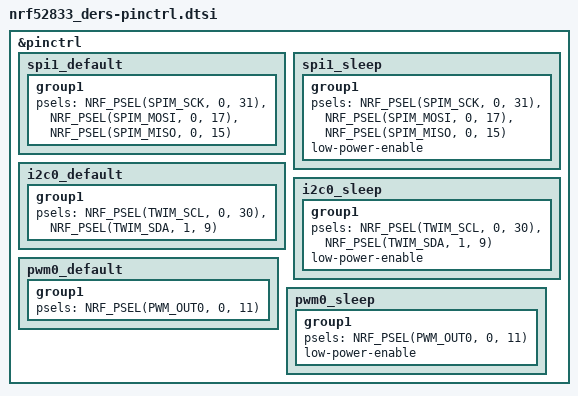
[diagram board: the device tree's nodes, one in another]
/* SPDX-License-Identifier: Apache-2.0 */

#include <dt-bindings/pinctrl/nrf-pinctrl.h>

&pinctrl {
	/* SPI1: SCK=P0.31, MOSI=P0.17, MISO=P0.15 */
	spi1_default: spi1_default {
		group1 {
			psels = <NRF_PSEL(SPIM_SCK,  0, 31)>,
			        <NRF_PSEL(SPIM_MOSI, 0, 17)>,
			        <NRF_PSEL(SPIM_MISO, 0, 15)>;
		};
	};
	spi1_sleep: spi1_sleep {
		group1 {
			psels = <NRF_PSEL(SPIM_SCK,  0, 31)>,
			        <NRF_PSEL(SPIM_MOSI, 0, 17)>,
			        <NRF_PSEL(SPIM_MISO, 0, 15)>;
			low-power-enable;
		};
	};

	/* I2C0: SCL=P0.30, SDA=P1.09 */
	i2c0_default: i2c0_default {
		group1 {
			psels = <NRF_PSEL(TWIM_SCL, 0, 30)>,
			        <NRF_PSEL(TWIM_SDA, 1,  9)>;
		};
	};
	i2c0_sleep: i2c0_sleep {
		group1 {
			psels = <NRF_PSEL(TWIM_SCL, 0, 30)>,
			        <NRF_PSEL(TWIM_SDA, 1,  9)>;
			low-power-enable;
		};
	};

	/* PWM0: DISP_LED_PWM = P0.11, gate of the display backlight NMOS */
	pwm0_default: pwm0_default {
		group1 {
			psels = <NRF_PSEL(PWM_OUT0, 0, 11)>;
		};
	};
	pwm0_sleep: pwm0_sleep {
		group1 {
			psels = <NRF_PSEL(PWM_OUT0, 0, 11)>;
			low-power-enable;
		};
	};
};
